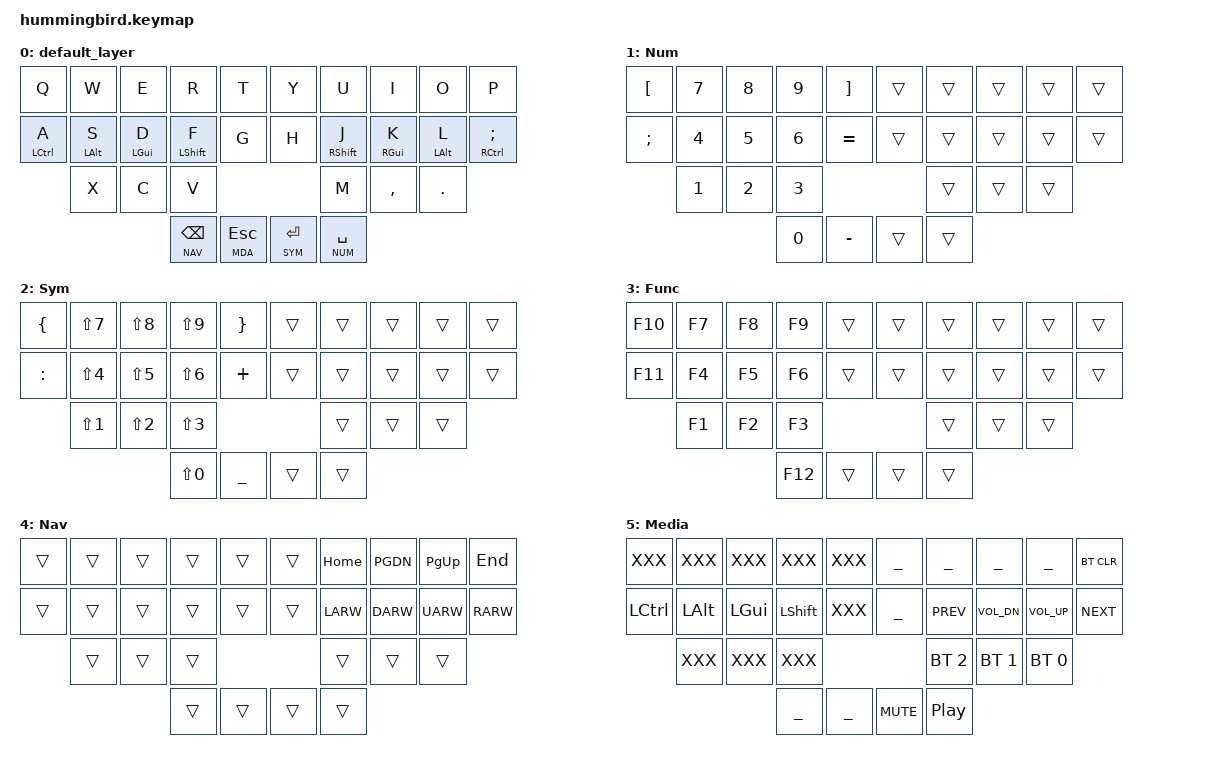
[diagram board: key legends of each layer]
/*
 * Copyright (c) 2022 The ZMK Contributors
 *
 * SPDX-License-Identifier: MIT
 */

#include <behaviors.dtsi>
#include <dt-bindings/zmk/keys.h>
#include <dt-bindings/zmk/bt.h>
#include "3X-key.h"

#define COMBO(NAME, TIMEOUT, BINDINGS, KEYPOS, LAYERS) \
    combo_##NAME { \
        timeout-ms = <TIMEOUT>; \
        key-positions = <KEYPOS>; \
        bindings = <BINDINGS>; \
        layers = <LAYERS>; \
    };

/ {
    behaviors {
        #include "behaviors.dtsi"
    };

    combos {
        compatible = "zmk,combos";

        // first attempt at missing alphas
        COMBO(Z, 40, &kp Z, 0 10, BASE)
        COMBO(B, 40, &kp B, 4 14, BASE)
        COMBO(N, 40, &kp N, 5 15, BASE)
        COMBO(SLASH, 40, &kp SLASH, 9 19, BASE)

        // second attempt at missing alphas
        COMBO(Za, 40, &kp Z, 10 11, BASE)
        COMBO(Ba, 40, &kp B, 12 22, BASE)
        COMBO(Na, 40, &kp N, 17 23, BASE)
        COMBO(Nb, 40, &kp N, 16 17, BASE)
        COMBO(Nc, 40, &kp N, 23 24, BASE)
        COMBO(SLASHa, 40, &kp SLASH, 18 19, BASE)

        // regular combos but adjusted key positions
	COMBO(DEL, 40, &kp DEL, 26 27, BASE)
        COMBO(FN, 40, &lt FUNC TAB, 28 29, BASE)
        COMBO(minus, 40, &kp MINUS,  6  7, BASE)
	COMBO(equal, 40, &kp EQUAL,  7  8, BASE)
	COMBO(quote, 40, &kp SQT,   17 18, BASE)
	COMBO(lbrc,  40, &kp LBRC,   1  2, BASE)
	COMBO(rbrc,  40, &kp RBRC,   2  3, BASE)
	COMBO(lbkt,  40, &kp LBKT,  11 12, BASE)
	COMBO(rbkt,  40, &kp RBKT,  12 13, BASE)
	COMBO(grave, 40, &kp GRAVE, 20 21, BASE)
	COMBO(tilde, 40, &kp TILDE, 21 22, BASE)
	COMBO(bslsh, 40, &kp BSLH,  24 25, BASE)
    };

    keymap {
        compatible = "zmk,keymap";

        default_layer {
            bindings = <
                &kp Q       &kp W      &kp E      &kp R           &kp T        &kp Y            &kp U          &kp I      &kp O      &kp P
                &hm LCTRL A &hm LALT S &hm LGUI D &hm LSHFT F     &kp G        &kp H            &hm RSHFT J    &hm RGUI K &hm LALT L &hm RCTRL SEMI
                            &kp X      &kp C      &kp V                                         &kp M          &kp COMMA  &kp DOT
                                                  &lt NAV BKSP    &lt MDA ESC  &lt SYM RET      &lt NUM SPACE
            >;
        };

        num_layer {
            label = "Num";
            bindings = <
                &kp LBKT   &kp N7     &kp N8      &kp N9          &kp RBKT      &trans          &trans         &trans      &trans     &trans
                &kp SEMI   &kp N4     &kp N5      &kp N6          &kp EQUAL     &trans          &trans         &trans      &trans     &trans
                           &kp N1     &kp N2      &kp N3                                        &trans         &trans      &trans
                                                  &kp N0          &kp MINUS     &trans          &trans
            >;
        };

        sym_layer {
            label = "Sym";
            bindings = <
                &kp LBRC   &kp LS(N7) &kp LS(N8)  &kp LS(N9)      &kp RBRC      &trans          &trans         &trans      &trans     &trans
                &kp COLON  &kp LS(N4) &kp LS(N5)  &kp LS(N6)      &kp PLUS      &trans          &trans         &trans      &trans     &trans
                           &kp LS(N1) &kp LS(N2)  &kp LS(N3)                                    &trans         &trans      &trans
                                                  &kp LS(N0)      &kp UNDER     &trans          &trans
            >;
        };

        function_layer {
            label = "Func";
            bindings = <
                &kp F10    &kp F7     &kp F8      &kp F9          &trans        &trans          &trans         &trans      &trans     &trans
                &kp F11    &kp F4     &kp F5      &kp F6          &trans        &trans          &trans         &trans      &trans     &trans
                           &kp F1     &kp F2      &kp F3                                        &trans         &trans      &trans
                                                  &kp F12         &trans        &trans          &trans
            >;
        };

        nav_layer {
            label = "Nav";
            bindings = <
                &trans     &trans     &trans      &trans          &trans       &trans           &kp HOME       &kp PGDN &kp PG_UP  &kp END
                &trans     &trans     &trans      &trans          &trans       &trans           &kp LARW       &kp DARW &kp UARW   &kp RARW
                           &trans     &trans      &trans                                        &trans         &trans   &trans
                                                  &trans          &trans       &trans           &trans
            >;
        };

        media_layer {
            label = "Media";
            bindings = <
                XXX      XXX      XXX      XXX       XXX  ___  ___            ___          ___          &bt BT_CLR
                &kp LCTL &kp LALT &kp LGUI &kp LSHFT XXX  ___  &kp C_PREV     &kp C_VOL_DN &kp C_VOL_UP &kp C_NEXT
                         XXX      XXX      XXX                 &bt BT_SEL 2   &bt BT_SEL 1 &bt BT_SEL 0
                                           ___       ___  &kp C_MUTE   &kp C_PLAY_PAUSE
            >;
        };
    };
};
